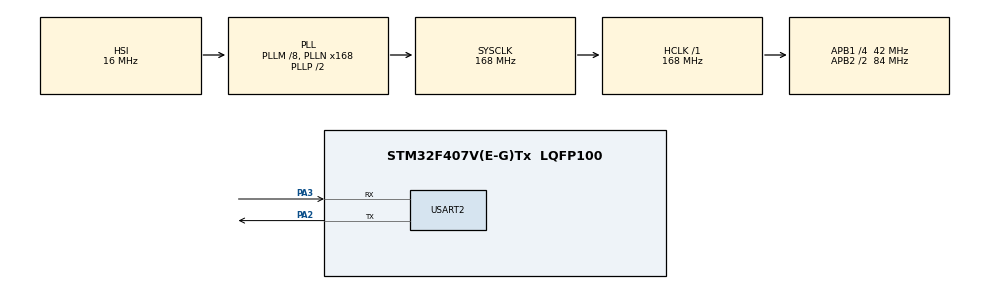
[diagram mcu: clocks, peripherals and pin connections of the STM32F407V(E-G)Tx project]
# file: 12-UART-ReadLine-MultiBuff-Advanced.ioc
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Mcu.Family=STM32F4
Mcu.Name=STM32F407V(E-G)Tx
Mcu.Package=LQFP100
NVIC.PriorityGroup=NVIC_PRIORITYGROUP_4
NVIC.USART2_IRQn=true\:0\:0\:false\:false\:true\:true\:true\:true
PA2.Mode=Asynchronous
PA2.Signal=USART2_TX
PA3.Mode=Asynchronous
PA3.Signal=USART2_RX
ProjectManager.HeapSize=0x200
ProjectManager.StackSize=0x400
ProjectManager.TargetToolchain=STM32CubeIDE
RCC.48MHZClocksFreq_Value=84000000
RCC.AHBFreq_Value=168000000
RCC.APB1CLKDivider=RCC_HCLK_DIV4
RCC.APB1Freq_Value=42000000
RCC.APB1TimFreq_Value=84000000
RCC.APB2CLKDivider=RCC_HCLK_DIV2
RCC.APB2Freq_Value=84000000
RCC.APB2TimFreq_Value=168000000
RCC.CortexFreq_Value=168000000
RCC.HCLKFreq_Value=168000000
RCC.HSE_VALUE=25000000
RCC.HSI_VALUE=16000000
RCC.LSE_VALUE=32768
RCC.PLLM=8
RCC.PLLN=168
RCC.SYSCLKFreq_VALUE=168000000
RCC.SYSCLKSource=RCC_SYSCLKSOURCE_PLLCLK
RCC.VCOOutputFreq_Value=336000000
USART2.VirtualMode=VM_ASYNC
board=custom

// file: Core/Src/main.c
/* USER CODE BEGIN Header */
/**
  ******************************************************************************
  * @file           : main.c
  * @brief          : Main program body
  ******************************************************************************
  * @attention
  *
  * <h2><center>&copy; Copyright (c) 2023 STMicroelectronics.
  * All rights reserved.</center></h2>
  *
  * This software component is licensed by ST under BSD 3-Clause license,
  * the "License"; You may not use this file except in compliance with the
  * License. You may obtain a copy of the License at:
  *                        opensource.org/licenses/BSD-3-Clause
  *
  ******************************************************************************
  */
/* USER CODE END Header */
#include "main.h"
#include "usart.h"
#include "gpio.h"

/* USER CODE BEGIN PTD */
#define RX_BUF_SIZE         64
#define RX_BUF_LEN          4

typedef struct {
  uint8_t       Buffer[RX_BUF_SIZE];
  uint16_t      Index;
  uint8_t       Flag;
} UART_MultiBuffer_Buf;

typedef struct {
  UART_HandleTypeDef*   HUART;
  UART_MultiBuffer_Buf  Buf[RX_BUF_LEN];
  uint8_t               ActiveBuffer;
  uint8_t               CurrentBuffer;
  uint8_t               Temp;
}UART_MultiBuffer;

/* USER CODE END PTD */

/* USER CODE BEGIN PV */
static UART_MultiBuffer uart2RxBuf;
/* USER CODE END PV */

void SystemClock_Config(void);
/* USER CODE BEGIN PFP */
void UART_MultiBuffer_init(UART_MultiBuffer* buf, UART_HandleTypeDef* huart);
void UART_MultiBuffer_process(UART_MultiBuffer* buf);
void UART_MultiBuffer_release(UART_MultiBuffer* buf);

uint8_t UART_MultiBuffer_checkFlag(UART_MultiBuffer* buf);
UART_MultiBuffer_Buf* UART_MultiBuffer_get(UART_MultiBuffer* buf);
/* USER CODE END PFP */

int main(void)
{

  /* MCU Configuration--------------------------------------------------------*/

  /* Reset of all peripherals, Initializes the Flash interface and the Systick. */
  HAL_Init();

  /* Configure the system clock */
  SystemClock_Config();

  /* Initialize all configured peripherals */
  MX_GPIO_Init();
  MX_USART2_UART_Init();

  /* Infinite loop */
  /* USER CODE BEGIN WHILE */
  UART_MultiBuffer_init(&uart2RxBuf, &huart2);
  while (1)
  {
    if (UART_MultiBuffer_checkFlag(&uart2RxBuf)) {
      UART_MultiBuffer_Buf* buf = UART_MultiBuffer_get(&uart2RxBuf);
      // Process
      HAL_UART_Transmit(&huart2, buf->Buffer, buf->Index, 1000);
      // Reset and goto next buffer
      UART_MultiBuffer_release(&uart2RxBuf);
    }
    /* USER CODE END WHILE */

  }
}

void SystemClock_Config(void)
{
  RCC_OscInitTypeDef RCC_OscInitStruct = {0};
  RCC_ClkInitTypeDef RCC_ClkInitStruct = {0};

  /** Configure the main internal regulator output voltage
  */
  __HAL_RCC_PWR_CLK_ENABLE();
  __HAL_PWR_VOLTAGESCALING_CONFIG(PWR_REGULATOR_VOLTAGE_SCALE1);
  /** Initializes the RCC Oscillators according to the specified parameters
  * in the RCC_OscInitTypeDef structure.
  */
  RCC_OscInitStruct.OscillatorType = RCC_OSCILLATORTYPE_HSI;
  RCC_OscInitStruct.HSIState = RCC_HSI_ON;
  RCC_OscInitStruct.HSICalibrationValue = RCC_HSICALIBRATION_DEFAULT;
  RCC_OscInitStruct.PLL.PLLState = RCC_PLL_ON;
  RCC_OscInitStruct.PLL.PLLSource = RCC_PLLSOURCE_HSI;
  RCC_OscInitStruct.PLL.PLLM = 8;
  RCC_OscInitStruct.PLL.PLLN = 168;
  RCC_OscInitStruct.PLL.PLLP = RCC_PLLP_DIV2;
  RCC_OscInitStruct.PLL.PLLQ = 4;
  if (HAL_RCC_OscConfig(&RCC_OscInitStruct) != HAL_OK)
  {
    Error_Handler();
  }
  /** Initializes the CPU, AHB and APB buses clocks
  */
  RCC_ClkInitStruct.ClockType = RCC_CLOCKTYPE_HCLK|RCC_CLOCKTYPE_SYSCLK
                              |RCC_CLOCKTYPE_PCLK1|RCC_CLOCKTYPE_PCLK2;
  RCC_ClkInitStruct.SYSCLKSource = RCC_SYSCLKSOURCE_PLLCLK;
  RCC_ClkInitStruct.AHBCLKDivider = RCC_SYSCLK_DIV1;
  RCC_ClkInitStruct.APB1CLKDivider = RCC_HCLK_DIV4;
  RCC_ClkInitStruct.APB2CLKDivider = RCC_HCLK_DIV2;

  if (HAL_RCC_ClockConfig(&RCC_ClkInitStruct, FLASH_LATENCY_5) != HAL_OK)
  {
    Error_Handler();
  }
}

/* USER CODE BEGIN 4 */
void HAL_UART_RxCpltCallback(UART_HandleTypeDef* huart) {
  switch ((uint32_t) huart->Instance) {
    case USART2_BASE:
      UART_MultiBuffer_process(&uart2RxBuf);
      break;
    default:

      break;
  }
}
void UART_MultiBuffer_init(UART_MultiBuffer* buf, UART_HandleTypeDef* huart) {
  buf->HUART = huart;
  buf->CurrentBuffer = 0;
  buf->ActiveBuffer = 0;
  for (uint8_t i = 0; i < RX_BUF_LEN; i++) {
    buf->Buf[i].Index = 0;
    buf->Buf[i].Flag = 0;
  }

  HAL_UART_Receive_IT(buf->HUART, &buf->Temp, sizeof(buf->Temp));
}
void UART_MultiBuffer_process(UART_MultiBuffer* buf) {
  UART_MultiBuffer_Buf* pBuf = &buf->Buf[buf->ActiveBuffer];
  // Fill buffer
  pBuf->Buffer[pBuf->Index++] = buf->Temp;
  // Check CRLF
  if (pBuf->Index >= 2 &&
      buf->Temp == '\n' &&
      pBuf->Buffer[pBuf->Index - 2] == '\r'
  ) {
    // Set Flag and change to next buffer
    pBuf->Flag = 1;
    if (++buf->ActiveBuffer == RX_BUF_LEN) {
      buf->ActiveBuffer = 0;
    }
  }
  // Receive next byte
  HAL_UART_Receive_IT(buf->HUART, &buf->Temp, sizeof(buf->Temp));
}
void UART_MultiBuffer_release(UART_MultiBuffer* buf) {
  buf->Buf[buf->CurrentBuffer].Flag = 0;
  buf->Buf[buf->CurrentBuffer].Index = 0;

  if (++buf->CurrentBuffer == RX_BUF_LEN) {
    buf->CurrentBuffer = 0;
  }
}

uint8_t UART_MultiBuffer_checkFlag(UART_MultiBuffer* buf) {
  return buf->Buf[buf->CurrentBuffer].Flag;
}

UART_MultiBuffer_Buf* UART_MultiBuffer_get(UART_MultiBuffer* buf) {
  return &buf->Buf[buf->CurrentBuffer];
}
/* USER CODE END 4 */

void Error_Handler(void)
{
  __disable_irq();
  while (1)
  {
  }
}

/************************ (C) COPYRIGHT STMicroelectronics *****END OF FILE****/
